VERSION ""

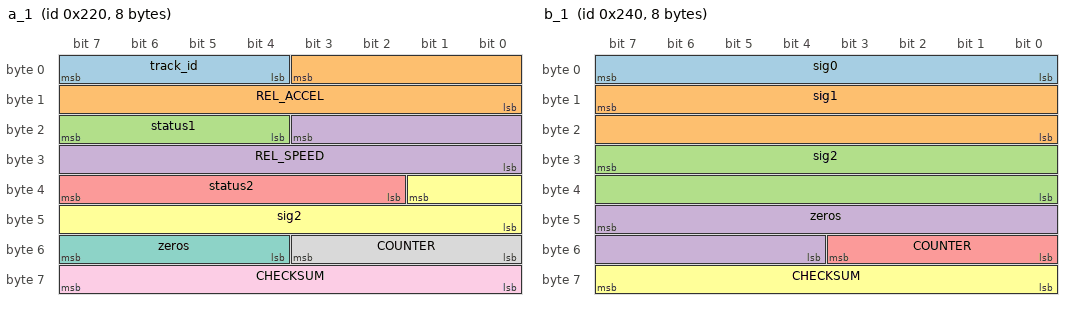
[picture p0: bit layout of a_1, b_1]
BO_ 544 a_1: 8 XXX
 SG_ track_id : 7|4@0+ (1,0) [0|15] "" XXX
 SG_ REL_ACCEL : 3|12@0+ (1,0) [0|31] "" XXX
 SG_ status1 : 23|4@0+ (1,0) [0|15] "" XXX
 SG_ REL_SPEED : 19|12@0+ (1,0) [0|65535] "" XXX
 SG_ status2 : 39|6@0+ (1,0) [0|15] "" XXX
 SG_ sig2 : 33|10@0+ (1,0) [0|255] "" XXX
 SG_ zeros : 55|4@0+ (1,0) [0|15] "" XXX
 SG_ COUNTER : 51|4@0+ (1,0) [0|15] "" XXX
 SG_ CHECKSUM : 63|8@0+ (1,0) [0|255] "" XXX

BO_ 576 b_1: 8 XXX
 SG_ sig0 : 7|8@0+ (1,0) [0|255] "" XXX
 SG_ sig1 : 15|16@0+ (1,0) [0|65535] "" XXX
 SG_ sig2 : 31|16@0+ (1,0) [0|255] "" XXX
 SG_ zeros : 47|12@0+ (1,0) [0|255] "" XXX
 SG_ COUNTER : 51|4@0+ (1,0) [0|15] "" XXX
 SG_ CHECKSUM : 63|8@0+ (1,0) [0|255] "" XXX

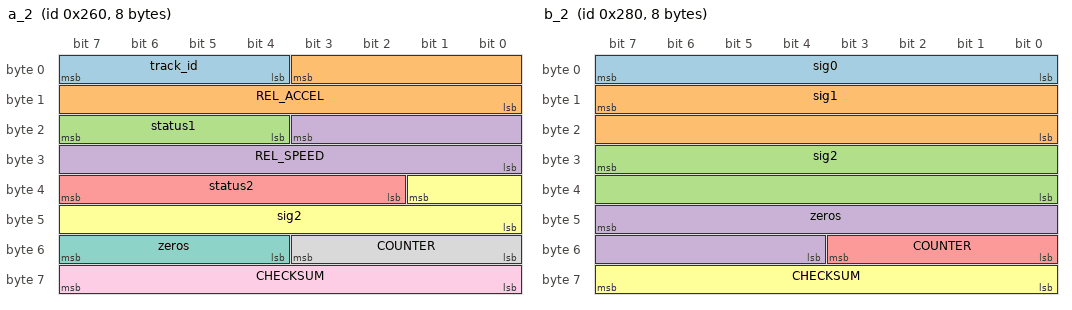
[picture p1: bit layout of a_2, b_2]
BO_ 608 a_2: 8 XXX
 SG_ track_id : 7|4@0+ (1,0) [0|15] "" XXX
 SG_ REL_ACCEL : 3|12@0+ (1,0) [0|31] "" XXX
 SG_ status1 : 23|4@0+ (1,0) [0|15] "" XXX
 SG_ REL_SPEED : 19|12@0+ (1,0) [0|65535] "" XXX
 SG_ status2 : 39|6@0+ (1,0) [0|15] "" XXX
 SG_ sig2 : 33|10@0+ (1,0) [0|255] "" XXX
 SG_ zeros : 55|4@0+ (1,0) [0|15] "" XXX
 SG_ COUNTER : 51|4@0+ (1,0) [0|15] "" XXX
 SG_ CHECKSUM : 63|8@0+ (1,0) [0|255] "" XXX

BO_ 640 b_2: 8 XXX
 SG_ sig0 : 7|8@0+ (1,0) [0|255] "" XXX
 SG_ sig1 : 15|16@0+ (1,0) [0|65535] "" XXX
 SG_ sig2 : 31|16@0+ (1,0) [0|255] "" XXX
 SG_ zeros : 47|12@0+ (1,0) [0|255] "" XXX
 SG_ COUNTER : 51|4@0+ (1,0) [0|15] "" XXX
 SG_ CHECKSUM : 63|8@0+ (1,0) [0|255] "" XXX

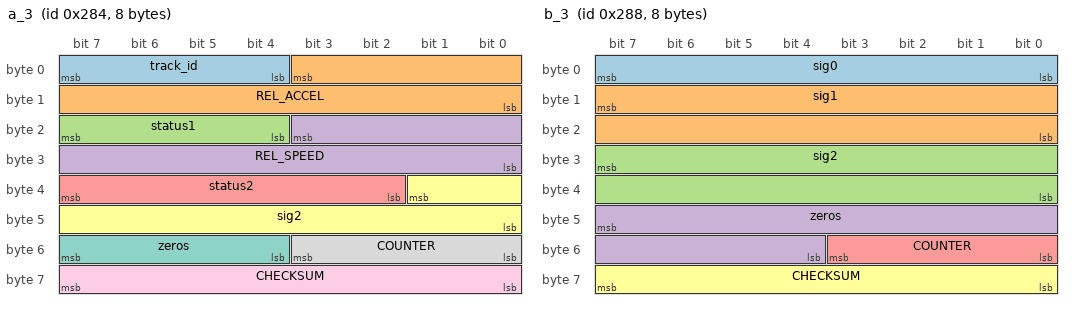
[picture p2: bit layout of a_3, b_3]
BO_ 644 a_3: 8 XXX
 SG_ track_id : 7|4@0+ (1,0) [0|15] "" XXX
 SG_ REL_ACCEL : 3|12@0+ (1,0) [0|31] "" XXX
 SG_ status1 : 23|4@0+ (1,0) [0|15] "" XXX
 SG_ REL_SPEED : 19|12@0+ (1,0) [0|65535] "" XXX
 SG_ status2 : 39|6@0+ (1,0) [0|15] "" XXX
 SG_ sig2 : 33|10@0+ (1,0) [0|255] "" XXX
 SG_ zeros : 55|4@0+ (1,0) [0|15] "" XXX
 SG_ COUNTER : 51|4@0+ (1,0) [0|15] "" XXX
 SG_ CHECKSUM : 63|8@0+ (1,0) [0|255] "" XXX

BO_ 648 b_3: 8 XXX
 SG_ sig0 : 7|8@0+ (1,0) [0|255] "" XXX
 SG_ sig1 : 15|16@0+ (1,0) [0|65535] "" XXX
 SG_ sig2 : 31|16@0+ (1,0) [0|255] "" XXX
 SG_ zeros : 47|12@0+ (1,0) [0|255] "" XXX
 SG_ COUNTER : 51|4@0+ (1,0) [0|15] "" XXX
 SG_ CHECKSUM : 63|8@0+ (1,0) [0|255] "" XXX

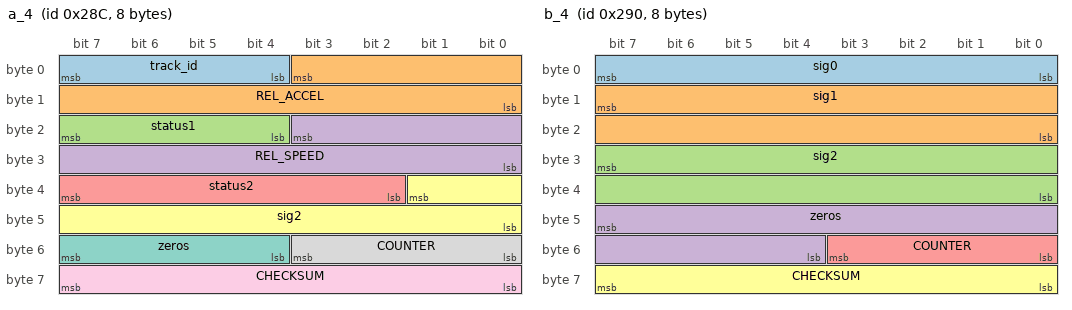
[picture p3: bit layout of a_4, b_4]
BO_ 652 a_4: 8 XXX
 SG_ track_id : 7|4@0+ (1,0) [0|15] "" XXX
 SG_ REL_ACCEL : 3|12@0+ (1,0) [0|31] "" XXX
 SG_ status1 : 23|4@0+ (1,0) [0|15] "" XXX
 SG_ REL_SPEED : 19|12@0+ (1,0) [0|65535] "" XXX
 SG_ status2 : 39|6@0+ (1,0) [0|15] "" XXX
 SG_ sig2 : 33|10@0+ (1,0) [0|255] "" XXX
 SG_ zeros : 55|4@0+ (1,0) [0|15] "" XXX
 SG_ COUNTER : 51|4@0+ (1,0) [0|15] "" XXX
 SG_ CHECKSUM : 63|8@0+ (1,0) [0|255] "" XXX

BO_ 656 b_4: 8 XXX
 SG_ sig0 : 7|8@0+ (1,0) [0|255] "" XXX
 SG_ sig1 : 15|16@0+ (1,0) [0|65535] "" XXX
 SG_ sig2 : 31|16@0+ (1,0) [0|255] "" XXX
 SG_ zeros : 47|12@0+ (1,0) [0|255] "" XXX
 SG_ COUNTER : 51|4@0+ (1,0) [0|15] "" XXX
 SG_ CHECKSUM : 63|8@0+ (1,0) [0|255] "" XXX

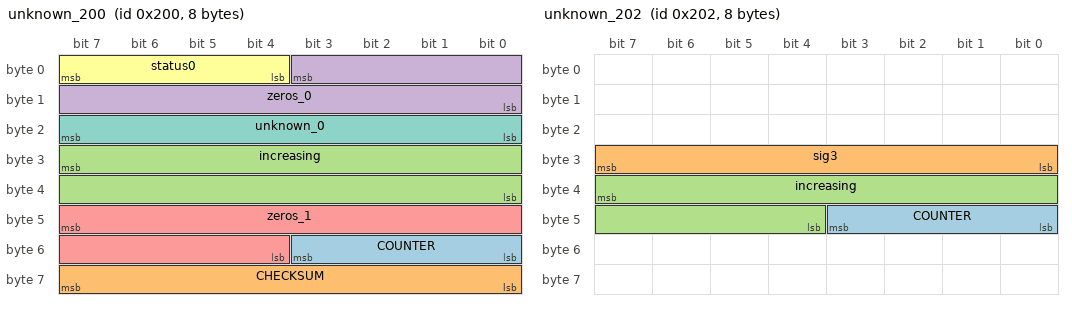
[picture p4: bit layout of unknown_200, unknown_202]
BO_ 512 unknown_200: 8 XXX
 SG_ COUNTER : 51|4@0+ (1,0) [0|15] "" XXX
 SG_ CHECKSUM : 63|8@0+ (1,0) [0|255] "" XXX
 SG_ increasing : 31|16@0+ (1,0) [0|255] "" XXX
 SG_ zeros_0 : 3|12@0+ (1,0) [0|63] "" XXX
 SG_ zeros_1 : 47|12@0+ (1,0) [0|63] "" XXX
 SG_ status0 : 7|4@0+ (1,0) [0|15] "" XXX
 SG_ unknown_0 : 23|8@0+ (1,0) [0|255] "" XXX

BO_ 514 unknown_202: 8 XXX
 SG_ COUNTER : 43|4@0+ (1,0) [0|15] "" XXX
 SG_ sig3 : 31|8@0+ (1,0) [0|65535] "" XXX
 SG_ increasing : 39|12@0+ (1,0) [0|15] "" XXX

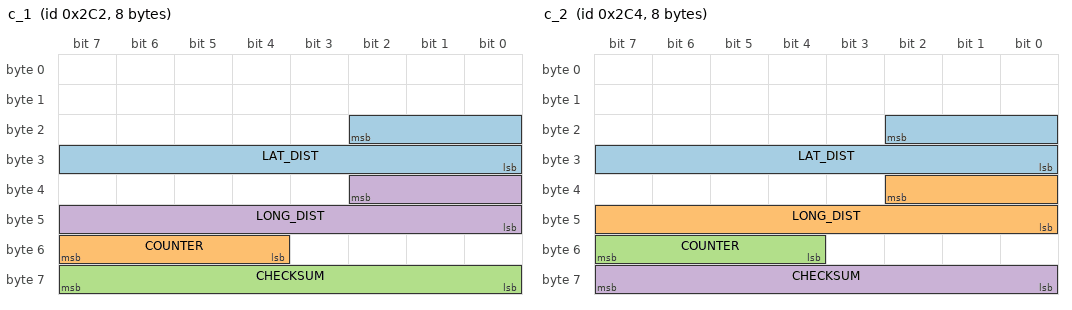
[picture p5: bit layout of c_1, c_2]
BO_ 706 c_1: 8 XXX
 SG_ LAT_DIST : 18|11@0+ (0.005,-1000) [0|2047] "m" XXX
 SG_ COUNTER : 55|4@0+ (1,0) [0|15] "" XXX
 SG_ CHECKSUM : 63|8@0+ (1,0) [0|255] "" XXX
 SG_ LONG_DIST : 34|11@0+ (0.073,0) [0|255] "m" XXX

BO_ 708 c_2: 8 XXX
 SG_ LAT_DIST : 18|11@0+ (0.005,-1000) [0|2047] "m" XXX
 SG_ LONG_DIST : 34|11@0+ (0.073,0) [0|255] "m" XXX
 SG_ COUNTER : 55|4@0+ (1,0) [0|15] "" XXX
 SG_ CHECKSUM : 63|8@0+ (1,0) [0|255] "" XXX

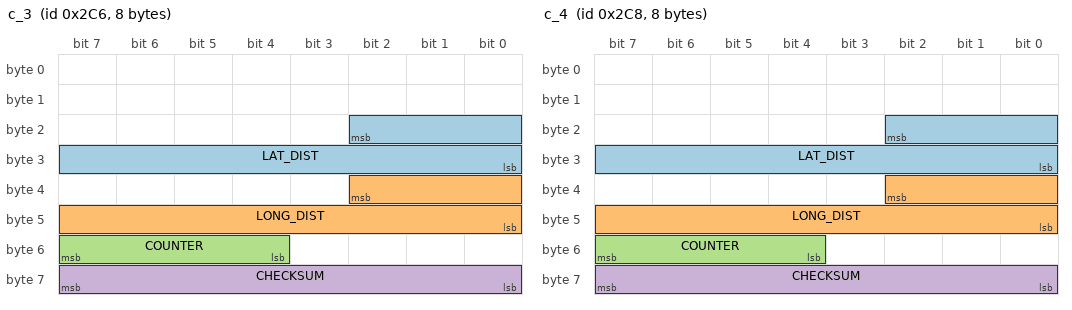
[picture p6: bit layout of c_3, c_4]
BO_ 710 c_3: 8 XXX
 SG_ LAT_DIST : 18|11@0+ (0.005,-1000) [0|2047] "m" XXX
 SG_ LONG_DIST : 34|11@0+ (0.073,0) [0|255] "m" XXX
 SG_ COUNTER : 55|4@0+ (1,0) [0|15] "" XXX
 SG_ CHECKSUM : 63|8@0+ (1,0) [0|255] "" XXX

BO_ 712 c_4: 8 XXX
 SG_ LAT_DIST : 18|11@0+ (0.005,-1000) [0|2047] "m" XXX
 SG_ LONG_DIST : 34|11@0+ (0.073,0) [0|255] "m" XXX
 SG_ COUNTER : 55|4@0+ (1,0) [0|15] "" XXX
 SG_ CHECKSUM : 63|8@0+ (1,0) [0|255] "" XXX

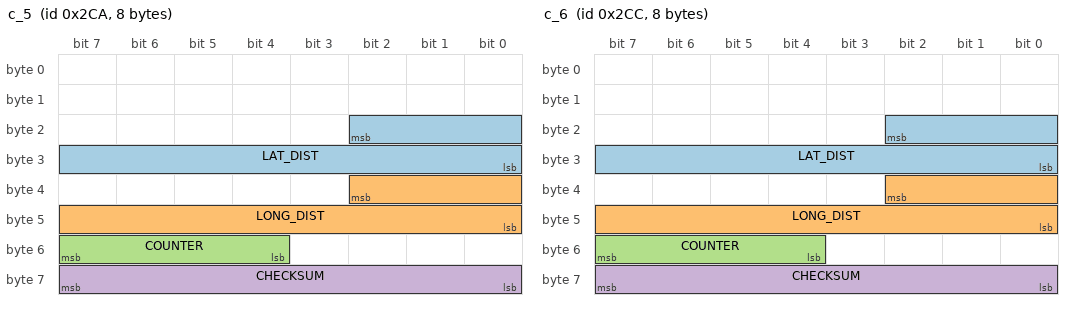
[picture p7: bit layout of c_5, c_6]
BO_ 714 c_5: 8 XXX
 SG_ LAT_DIST : 18|11@0+ (0.005,-1000) [0|2047] "m" XXX
 SG_ LONG_DIST : 34|11@0+ (0.073,0) [0|255] "m" XXX
 SG_ COUNTER : 55|4@0+ (1,0) [0|15] "" XXX
 SG_ CHECKSUM : 63|8@0+ (1,0) [0|255] "" XXX

BO_ 716 c_6: 8 XXX
 SG_ LAT_DIST : 18|11@0+ (0.005,-1000) [0|2047] "m" XXX
 SG_ LONG_DIST : 34|11@0+ (0.073,0) [0|255] "m" XXX
 SG_ COUNTER : 55|4@0+ (1,0) [0|15] "" XXX
 SG_ CHECKSUM : 63|8@0+ (1,0) [0|255] "" XXX

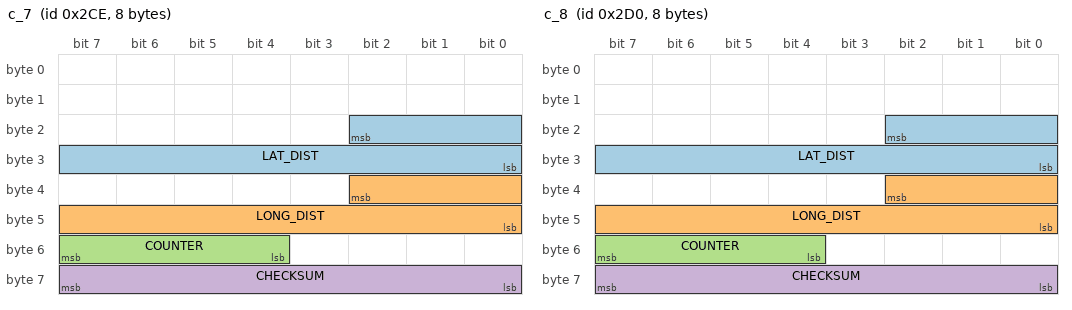
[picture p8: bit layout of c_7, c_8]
BO_ 718 c_7: 8 XXX
 SG_ LAT_DIST : 18|11@0+ (0.005,-1000) [0|2047] "m" XXX
 SG_ LONG_DIST : 34|11@0+ (0.073,0) [0|255] "m" XXX
 SG_ COUNTER : 55|4@0+ (1,0) [0|15] "" XXX
 SG_ CHECKSUM : 63|8@0+ (1,0) [0|255] "" XXX

BO_ 720 c_8: 8 XXX
 SG_ LAT_DIST : 18|11@0+ (0.005,-1000) [0|2047] "m" XXX
 SG_ LONG_DIST : 34|11@0+ (0.073,0) [0|255] "m" XXX
 SG_ COUNTER : 55|4@0+ (1,0) [0|15] "" XXX
 SG_ CHECKSUM : 63|8@0+ (1,0) [0|255] "" XXX

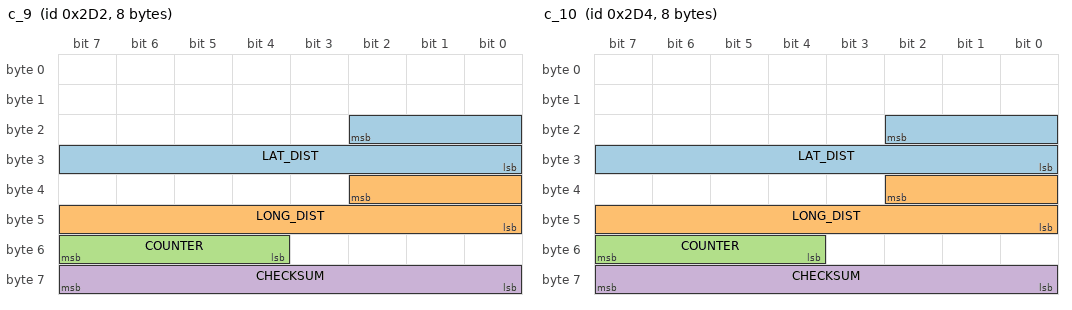
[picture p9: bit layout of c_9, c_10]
BO_ 722 c_9: 8 XXX
 SG_ LAT_DIST : 18|11@0+ (0.005,-1000) [0|2047] "m" XXX
 SG_ LONG_DIST : 34|11@0+ (0.073,0) [0|255] "m" XXX
 SG_ COUNTER : 55|4@0+ (1,0) [0|15] "" XXX
 SG_ CHECKSUM : 63|8@0+ (1,0) [0|255] "" XXX

BO_ 724 c_10: 8 XXX
 SG_ LAT_DIST : 18|11@0+ (0.005,-1000) [0|2047] "m" XXX
 SG_ LONG_DIST : 34|11@0+ (0.073,0) [0|255] "m" XXX
 SG_ COUNTER : 55|4@0+ (1,0) [0|15] "" XXX
 SG_ CHECKSUM : 63|8@0+ (1,0) [0|255] "" XXX

BO_ 674 d_1: 8 XXX
 SG_ REL_SPEED : 17|10@0+ (0.2857,-146.278) [0|1023] "m/s" XXX

BO_ 676 d_2: 8 XXX
 SG_ REL_SPEED : 17|10@0+ (0.2857,-146.278) [0|1023] "m/s" XXX

BO_ 678 d_3: 8 XXX
 SG_ REL_SPEED : 17|10@0+ (0.2857,-146.278) [0|1023] "m/s" XXX

BO_ 680 d_4: 8 XXX
 SG_ REL_SPEED : 17|10@0+ (0.2857,-146.278) [0|1023] "m/s" XXX

BO_ 682 d_5: 8 XXX
 SG_ REL_SPEED : 17|10@0+ (0.2857,-146.278) [0|1023] "m/s" XXX

BO_ 684 d_6: 8 XXX
 SG_ REL_SPEED : 17|10@0+ (0.2857,-146.278) [0|1023] "m/s" XXX

BO_ 686 d_7: 8 XXX
 SG_ REL_SPEED : 17|10@0+ (0.2857,-146.278) [0|1023] "m/s" XXX

BO_ 688 d_8: 8 XXX
 SG_ REL_SPEED : 17|10@0+ (0.2857,-146.278) [0|1023] "m/s" XXX

BO_ 690 d_9: 8 XXX
 SG_ REL_SPEED : 17|10@0+ (0.2857,-146.278) [0|1023] "m/s" XXX

BO_ 692 d_10: 8 XXX
 SG_ REL_SPEED : 17|10@0+ (0.2857,-146.278) [0|1023] "m/s" XXX

BO_ 672 NEW_MSG_5: 8 XXX
 SG_ NEW_SIGNAL_1 : 9|10@0+ (1,0) [0|1023] "" XXX
 SG_ NEW_SIGNAL_2 : 45|10@0+ (1,0) [0|1023] "" XXX

BU_: XXX

CM_ SG_ 80 Checksumme_Airbag_1 "Checksum Airbag_1";
CM_ SG_ 80 Zaehler_Airbag_1 "Counter Airbag_1";

CM_ SG_ 210 LM_Offset "centiNewton-meters for ease of calculation without FP math in Panda";
CM_ SG_ 210 Vib_Amp "Steering wheel haptic, amplitude";
CM_ SG_ 210 Vib_Freq "Steering wheel haptic, frequency";

CM_ SG_ 416 Zaehler_Bremse_1 "Counter Bremse_1";

CM_ SG_ 640 inneres_Motor_Moment "Engine Indicated Torque";
CM_ SG_ 640 Fahrerwunschmoment "Driver Requested Torque";
CM_ SG_ 640 mechanisches_Motor_Verlustmomen "Mechanical Torque Loss";
CM_ SG_ 640 Fahrpedalwert_oder_Drosselklapp "Accelerator Pedal or Throttle Position";
CM_ SG_ 640 Motordrehzahl "Engine Speed";
CM_ SG_ 640 Momentenangaben_ungenau "Approximate Torque Values";
CM_ SG_ 640 inneres_Motor_Moment_ohne_exter "Inner torque without external";

CM_ SG_ 644 MOB_CHECKSUM "Checksum MOB";
CM_ SG_ 644 MOB_COUNTER "Counter MOB";

CM_ SG_ 648 Minimales_Motormoment_bei_Zuend "Minimum Torque Adjustment";
CM_ SG_ 648 Begrenzungsmoment "Maximum Inner Torque";
CM_ SG_ 648 Bremstestschalter "Brake Test Switch";
CM_ SG_ 648 Soll_Geschwindigkeit_bei_GRA_Be "Desired Vehicle Speed";
CM_ SG_ 648 Bremslichtschalter "Brake Light Switch";
CM_ SG_ 648 Leerlaufsolldrehzahl__Motor_2_ "Target Idle Speed";
CM_ SG_ 648 Fahrzeuggeschwindigkeit "Vehicle Speed";
CM_ SG_ 648 Kuehlmitteltemperatur__Motor_2_ "Coolant Temperature";

CM_ SG_ 896 Drosselklappenpoti "Throttle Position";
CM_ SG_ 896 Motor_Wunschdrehzahl "Desired engine speed";
CM_ SG_ 896 Motordrehzahlbeeinflussung "Shift Target Influence";
CM_ SG_ 896 Fahrpedal_Rohsignal "Accelerator Pedal Position";
CM_ SG_ 896 Ansauglufttemperatur "Intake Air Temperature";
CM_ SG_ 896 Kein_E_Gas "ETB flag";
CM_ SG_ 896 Kein_Start_Stop "Start/stop flag";
CM_ SG_ 896 Rad_Wunschmoment "Desired wheel torque";

CM_ SG_ 912 GK1_Fa_Tuerkont "Status of the driver's door rotary latch";
CM_ SG_ 912 BSK_HL_geoeffnet "Status of the rear left door rotary latch";
CM_ SG_ 912 BSK_HR_geoeffnet "Status of the rear right door rotary latch";
CM_ SG_ 912 BSK_BT_geoeffnet "Status of the passenger door rotary latch";
CM_ SG_ 912 BSK_HD_Hauptraste "Status of trunk lid main detent";

CM_ SG_ 1088 Zaehler_Getriebe_1 "Counter Getriebe_1";
CM_ SG_ 1088 Waehlhebelposition__Getriebe_1_ "Gear Selector Position";
CM_ SG_ 1088 inneres_Soll_Motormoment "Desired Inner Torque";
CM_ SG_ 1088 Schaltabsicht "Shift Intent";
CM_ SG_ 1088 Wandlerverlustmoment "Converter Torque Loss";

CM_ SG_ 1056 Fehlerstatus_Aussentemp__4_1 "ambient temp error";
CM_ SG_ 1056 Fehlerstatus_Oeltemperatur_4_1 "oil temp error";
CM_ SG_ 1056 Fehlerst__Kuehlmitteltemp__4_1 "water temp error";
CM_ SG_ 1056 Aussentemperatur_gefiltert "outside temp, filtered";
CM_ SG_ 1056 Oeltemperatur_4_1 "kombi oil temperature";
CM_ SG_ 1056 Kuehlmitteltemp__4_1__Kombi_2_ "kombi coolant temperature";

CM_ SG_ 1096 Zaehler_Waehlhebel_1 "Counter Waehlhebel_1";

CM_ SG_ 1152 CHECKSUM "Checksum Motor_5";
CM_ SG_ 1152 Anlasser_Ausspuren "Starter Disable";
CM_ SG_ 1152 Anlasser_Freigabe "Starter Release";
CM_ SG_ 1152 Klimadrucksignal__Motor_5_ "Air conditioning pressure signal";
CM_ SG_ 1152 Kraftstoffverbrauchssignal "Fuel consumption signal";
CM_ SG_ 1152 K_hlerluefteransteuerung "Cooling fan control signal";
CM_ SG_ 1152 Klimakompressor_Leistungsreduzi "Air conditioning compressor power reduction flag";
CM_ SG_ 1152 Klimakompressor_aus__Motor_5_ "Air conditioning compressor";
CM_ SG_ 1152 Anlasser_Freigabe "Starter release";
CM_ SG_ 1152 OBD_2_Lampe "OBD light";
CM_ SG_ 1152 E_Gas_Lampe "ETB light";
CM_ SG_ 1152 Ladekontroll_Lampe "Charge light";
CM_ SG_ 1152 Vorgluehlampe__Motor_5_ "Glow light";

CM_ SG_ 1160 Zaehler_Motor_6 "Counter Motor_6";
CM_ SG_ 1160 Hoeheninfo__Motor_6_ "Altitude Correction";
CM_ SG_ 1160 Istmoment_f_r_Getriebe "Actual torque for gear";
CM_ SG_ 1160 Sollmoment_f_r_Getriebe "Target torque for gearbox";
CM_ SG_ 1160 Checksumme_Motor_6 "Checksum Motor_6";
CM_ SG_ 1160 GRA_Sollbeschleunigung "GRA target acceleration";
CM_ SG_ 1160 Ruckmeldung_Momenten "Feedback torque-integral gear intervention";

CM_ SG_ 1344 Zahler_Getriebe_2 "Counter Getriebe_2";
CM_ SG_ 1344 Hochschaltlampe "Upshift Flag";

CM_ SG_ 1386 ACA_V_Wunsch "255=unset";

CM_ SG_ 1408 Zaehler_Motor_Flexia "Counter Motor_Flexia";
CM_ SG_ 1408 Verbrennungsart "Type of combustion";
CM_ SG_ 1408 Max_Drehmoment "Maximum torque";
CM_ SG_ 1408 Drehzahl_MaxNorm "RPM of maximum torque";
CM_ SG_ 1408 Hubraum "Displacement";
CM_ SG_ 1408 Anzahl_Zylinder "Number of cylinders";
CM_ SG_ 1408 Anzahl_Ventile "Number of valves";
CM_ SG_ 1408 Ansaugsystem "Induction System";
CM_ SG_ 1408 Motorleistung "Maximum engine power";

CM_ SG_ 1416 Ladedruck "Boost Pressure";
CM_ SG_ 1416 Motordrehzahlgradient "Engine speed gradient";
CM_ SG_ 1416 Hoeheninfo__Motor_7_ "Altitude correction factor";
CM_ SG_ 1416 Oltemperatur "Oil temperature";

CM_ SG_ 1470 LDW_Direction "0=right,1=left";
CM_ SG_ 1470 XX_DLCORTLC1 "Might be DLC or TLC";
CM_ SG_ 1470 XX_DLCORTLC2 "Might be DLC or TLC, might have wrong size";

CM_ SG_ 1550 MFA_v_Signal_02 "0=km/h, 1=mph";

VAL_ 513 STATE 5 "FAULT_TIMEOUT" 4 "FAULT_STARTUP" 3 "FAULT_SCE" 2 "FAULT_SEND" 1 "FAULT_BAD_CHECKSUM" 0 "NO_FAULT" ;

VAL_ 780 CRUISE_SPEED 255 "no_speed" 252 "stopped";
VAL_ 780 HUD_LEAD 3 "acc_off" 2 "solid_car" 1 "dashed_car" 0 "no_car";
VAL_ 884 DASHBOARD_ALERT 0 "none" 51 "acc_problem" 55 "cmbs_problem" 75 "key_not_detected" 79 "fasten_seatbelt" 111 "lkas_problem" 131 "brake_system_problem" 132 "brake_hold_problem" 139 "tbd" 161 "door_open";
VAL_ 891 WIPERS 4 "High" 2 "Low" 0 "Off";

VAL_ 399 STEER_STATUS 6 "tmp_fault" 5 "fault_1" 4 "no_torque_alert_2" 3 "low_speed_lockout" 2 "no_torque_alert_1" 0 "normal";

VAL_ 401 GEAR_SHIFTER 32 "L" 16 "S" 8 "D" 4 "N" 2 "R" 1 "P";
VAL_ 401 GEAR 7 "L" 10 "S" 4 "D" 3 "N" 2 "R" 1 "P";
